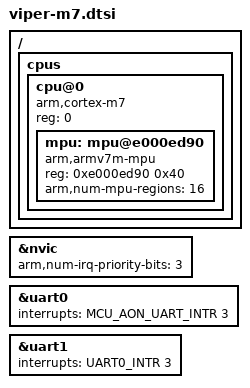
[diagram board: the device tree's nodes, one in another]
/* SPDX-License-Identifier: Apache-2.0 */
/*
 * Copyright 2020 Broadcom.
 */

#include <arm/armv7-m.dtsi>
#include <broadcom/viper-m7-irq.h>

#include "viper-common.dtsi"

/ {
	cpus {
		#address-cells = <1>;
		#size-cells = <0>;

		cpu@0 {
			device_type = "cpu";
			compatible = "arm,cortex-m7";
			reg = <0>;
			#address-cells = <1>;
			#size-cells = <1>;

			mpu: mpu@e000ed90 {
				compatible = "arm,armv7m-mpu";
				reg = <0xe000ed90 0x40>;
				arm,num-mpu-regions = <16>;
			};
		};
	};
};

&nvic {
	arm,num-irq-priority-bits = <3>;
};

&uart0 {
	interrupts = <MCU_AON_UART_INTR 3>;
};

&uart1 {
	interrupts = <UART0_INTR 3>;
};
